BO_ 717 ASCM_2CD: 5 K124_ASCM

BO_ 869 ASCM_365: 4 K124_ASCM

BO_ 1034 ASCM_40A: 7 K124_ASCM

BO_ 1296 ASCM_510: 4 K124_ASCM

BO_ 1930 ASCM_78A: 7 K124_ASCM

BO_ 190 ECMAcceleratorPos: 6 K20_ECM
 SG_ BrakePedalPos : 15|8@0+ (1,0) [0|0] "sticky"  NEO
 SG_ GasPedalAndAcc : 23|8@0+ (1,0) [0|0] ""  NEO

BO_ 201 ECMEngineStatus: 8 K20_ECM
 SG_ EngineTPS : 39|8@0+ (0.392156863,0) [0|100.000000065] "%"  NEO
 SG_ EngineRPM : 15|16@0+ (0.25,0) [0|0] "RPM"  NEO

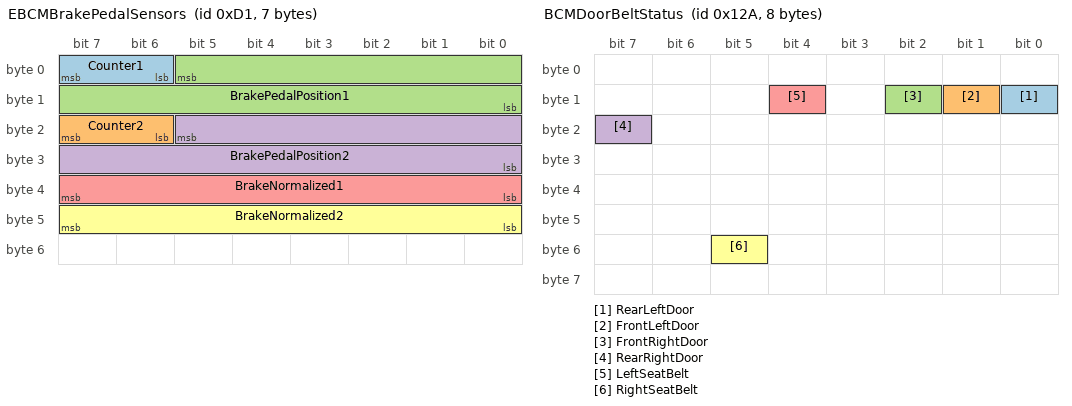
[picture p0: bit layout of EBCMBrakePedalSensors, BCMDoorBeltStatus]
BO_ 209 EBCMBrakePedalSensors: 7 K17_EBCM
 SG_ Counter1 : 7|2@0+ (1,0) [0|3] "" XXX
 SG_ Counter2 : 23|2@0+ (1,0) [0|3] "" XXX
 SG_ BrakePedalPosition1 : 5|14@0+ (1,0) [0|16383] "" XXX
 SG_ BrakePedalPosition2 : 21|14@0- (-1,0) [0|16383] "" XXX
 SG_ BrakeNormalized1 : 39|8@0+ (1,0) [0|255] "" XXX
 SG_ BrakeNormalized2 : 47|8@0- (-1,0) [0|255] "" XXX

BO_ 241 EBCMBrakePedalPosition: 6 K17_EBCM
 SG_ BrakePedalPosition : 15|8@0+ (1,0) [0|255] ""  NEO

BO_ 298 BCMDoorBeltStatus: 8 K9_BCM
 SG_ RearLeftDoor : 8|1@0+ (1,0) [0|0] ""  NEO
 SG_ FrontLeftDoor : 9|1@0+ (1,0) [0|0] ""  NEO
 SG_ FrontRightDoor : 10|1@0+ (1,0) [0|0] ""  NEO
 SG_ RearRightDoor : 23|1@0+ (1,0) [0|0] ""  NEO
 SG_ LeftSeatBelt : 12|1@0+ (1,0) [0|0] ""  NEO
 SG_ RightSeatBelt : 53|1@0+ (1,0) [0|0] ""  NEO

BO_ 309 ECMPRDNL: 8 K20_ECM
 SG_ PRNDL : 2|3@0+ (1,0) [0|0] ""  NEO

BO_ 320 BCMTurnSignals: 3 K9_BCM
 SG_ TurnSignals : 19|2@0+ (1,0) [0|0] ""  NEO

BO_ 336 ASCMLKASStatus: 1 NEO
 SG_ Available : 7|1@0+ (1,0) [0|0] ""  NEO

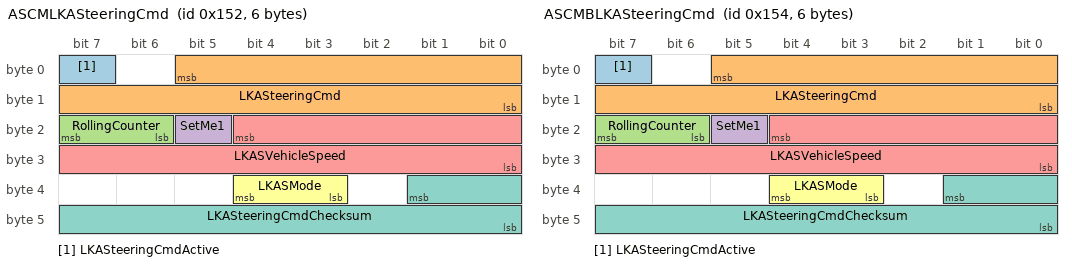
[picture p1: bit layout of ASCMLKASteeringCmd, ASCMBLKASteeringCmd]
BO_ 338 ASCMLKASteeringCmd: 6 NEO
 SG_ LKASteeringCmdActive : 7|1@0+ (1,0) [0|0] ""  NEO
 SG_ LKASteeringCmd : 5|14@0- (1,0) [0|0] ""  NEO
 SG_ RollingCounter : 23|2@0+ (1,0) [0|0] ""  NEO
 SG_ SetMe1 : 21|1@0+ (1,0) [0|0] ""  NEO
 SG_ LKASVehicleSpeed : 20|13@0+ (0.22,0) [0|0] "kph" NEO
 SG_ LKASMode : 36|2@0+ (1,0) [0|0] ""  NEO
 SG_ LKASteeringCmdChecksum : 33|10@0+ (1,0) [0|0] ""  NEO

BO_ 340 ASCMBLKASteeringCmd: 6 NEO
 SG_ LKASteeringCmdActive : 7|1@0+ (1,0) [0|0] ""  NEO
 SG_ LKASteeringCmd : 5|14@0- (1,0) [0|0] ""  NEO
 SG_ RollingCounter : 23|2@0+ (1,0) [0|0] ""  NEO
 SG_ SetMe1 : 21|1@0+ (1,0) [0|0] ""  NEO
 SG_ LKASVehicleSpeed : 20|13@0+ (0.22,0) [0|0] "kph" NEO
 SG_ LKASMode : 36|2@0+ (1,0) [0|0] ""  NEO
 SG_ LKASteeringCmdChecksum : 33|10@0+ (1,0) [0|0] ""  NEO

BO_ 381 MSG_17D: 8 K20_ECM
 SG_ MSG17D_AccPower : 35|12@0- (1,0) [0|0] ""  NEO

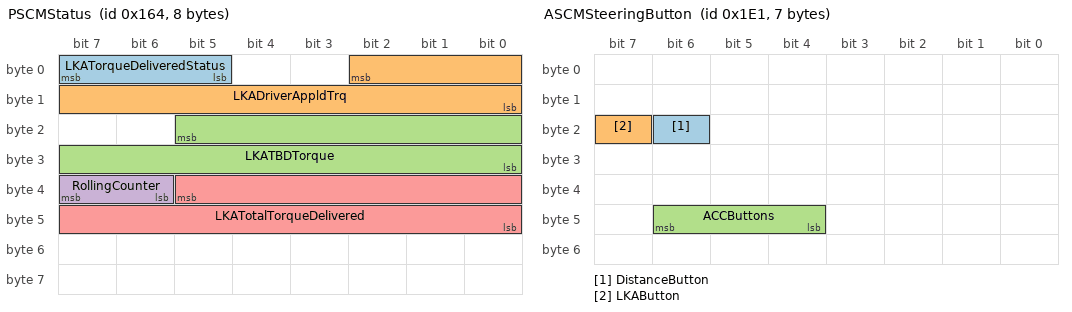
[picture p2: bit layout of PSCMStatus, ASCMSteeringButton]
BO_ 356 PSCMStatus: 8 K43_PSCM
 SG_ LKATorqueDeliveredStatus : 7|3@0+ (1,0) [0|7] ""  NEO
 SG_ LKADriverAppldTrq : 2|11@0- (0.01,0) [-10.24|10.23] "Nm"  NEO
 SG_ LKATBDTorque : 21|14@0- (-0.005,0) [-10.24|10.23] "Nm"  NEO
 SG_ RollingCounter : 39|2@0+ (1,0) [0|0] ""  NEO
 SG_ LKATotalTorqueDelivered : 37|14@0- (0.01,0) [-10.24|10.23] "Nm"  NEO

BO_ 417 AcceleratorPedal: 7 XXX
 SG_ AcceleratorPedal : 55|8@0+ (1,0) [0|0] ""  NEO

BO_ 451 GasAndAcc: 8 XXX
 SG_ GasPedalAndAcc2 : 55|8@0+ (1,0) [0|0] ""  NEO

BO_ 452 AcceleratorPedal2: 8 XXX
 SG_ AcceleratorPedal2 : 47|8@0+ (1,0) [0|0] ""  NEO

BO_ 481 ASCMSteeringButton: 7 K124_ASCM
 SG_ DistanceButton : 22|1@0+ (1,0) [0|0] ""  NEO
 SG_ LKAButton : 23|1@0+ (1,0) [0|0] ""  NEO
 SG_ ACCButtons : 46|3@0+ (1,0) [0|0] ""  NEO

BO_ 485 PSCMSteeringAngle: 8 K43_PSCM
 SG_ SteeringWheelAngle : 15|16@0- (0.0625,0) [-2047|2047] "deg"  NEO
 SG_ SteeringWheelRate : 27|12@0- (1,0) [-2047|2047] "deg/s"  NEO

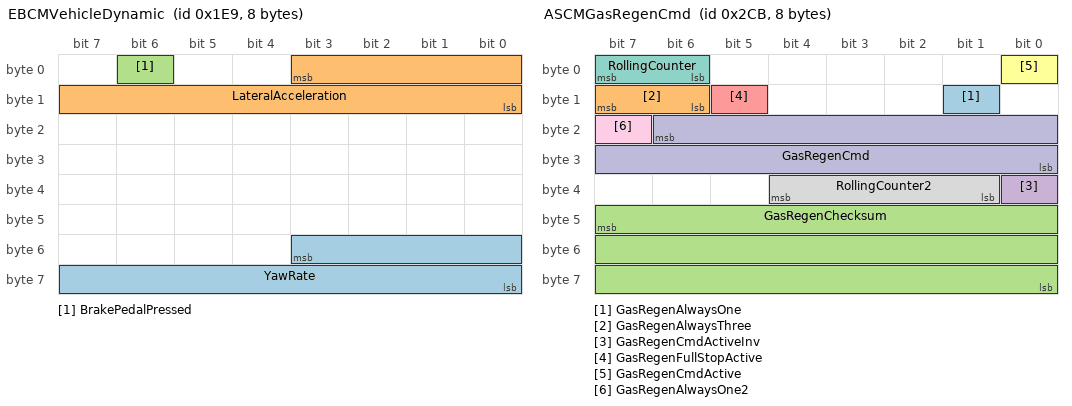
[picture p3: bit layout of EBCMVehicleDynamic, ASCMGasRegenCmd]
BO_ 489 EBCMVehicleDynamic: 8 K17_EBCM
 SG_ YawRate : 51|12@0- (0.0625,0) [-2047|2047] "grad/s"  NEO
 SG_ LateralAcceleration : 3|12@0- (0.0161,0) [-2047|2047] "m/s2"  NEO
 SG_ BrakePedalPressed : 6|1@0+ (1,0) [0|0] ""  NEO

BO_ 711 BECMBatteryVoltageCurrent: 6 K17_EBCM
 SG_ HVBatteryVoltage : 31|12@0+ (0.125,0) [0|511.875] "V"  NEO
 SG_ HVBatteryCurrent : 12|13@0- (0.15,0) [-614.4|614.25] "A"  NEO

BO_ 715 ASCMGasRegenCmd: 8 K124_ASCM
 SG_ GasRegenAlwaysOne : 9|1@0+ (1,1) [1|1] ""  NEO
 SG_ GasRegenAlwaysThree : 15|2@0+ (1,1) [1|1] ""  NEO
 SG_ GasRegenChecksum : 47|24@0+ (1,0) [0|0] ""  NEO
 SG_ GasRegenCmdActiveInv : 32|1@0+ (1,0) [0|0] ""  NEO
 SG_ GasRegenFullStopActive : 13|1@0+ (1,0) [0|0] ""  NEO
 SG_ GasRegenCmdActive : 0|1@0+ (1,0) [0|0] ""  NEO
 SG_ RollingCounter : 7|2@0+ (1,0) [0|0] ""  NEO
 SG_ RollingCounter2 : 36|4@0+ (1,0) [0|0] ""  NEO
 SG_ GasRegenAlwaysOne2 : 23|1@0+ (1,0) [0|1] ""  NEO
 SG_ GasRegenCmd : 22|15@0+ (1,0) [0|0] ""  NEO

BO_ 810 TCICOnStarGPSPosition: 8 K73_TCIC
 SG_ GPSLongitude : 39|32@0+ (1,-2147483648) [0|0] "milliarcsecond"  NEO
 SG_ GPSLatitude : 7|32@0+ (1,0) [0|0] "milliarcsecond"  NEO

BO_ 840 EBCMWheelSpdFront: 4 K17_EBCM
 SG_ FLWheelSpd : 7|16@0+ (0.0311,0) [0|255] "km/h"  NEO
 SG_ FRWheelSpd : 23|16@0+ (0.0311,0) [0|255] "km/h"  NEO

BO_ 842 EBCMWheelSpdRear: 4 K17_EBCM
 SG_ RLWheelSpd : 7|16@0+ (0.0311,0) [0|255] "km/h"  NEO
 SG_ RRWheelSpd : 23|16@0+ (0.0311,0) [0|255] "km/h"  NEO

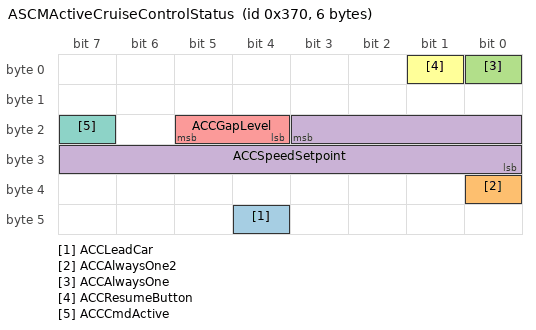
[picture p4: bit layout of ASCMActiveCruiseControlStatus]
BO_ 880 ASCMActiveCruiseControlStatus: 6 K124_ASCM
 SG_ ACCLeadCar : 44|1@0+ (1,0) [0|0] "" Vector__XXX
 SG_ ACCAlwaysOne2 : 32|1@0+ (1,0) [0|0] "" Vector__XXX
 SG_ ACCAlwaysOne : 0|1@0+ (1,0) [0|0] "" Vector__XXX
 SG_ ACCSpeedSetpoint : 19|12@0+ (0.0625,0) [0|255.9375] "km/h"  NEO
 SG_ ACCGapLevel : 21|2@0+ (1,0) [0|0] ""  NEO
 SG_ ACCResumeButton : 1|1@0+ (1,0) [0|0] ""  NEO
 SG_ ACCCmdActive : 23|1@0+ (1,0) [0|0] ""  NEO

BO_ 1001 ECMVehicleSpeed: 8 K20_ECM
 SG_ VehicleSpeed : 7|16@0+ (0.01,0) [0|0] "mph"  NEO

BO_ 1033 ASCMKeepAlive: 7 NEO
 SG_ ASCMKeepAliveAllZero : 7|56@0+ (1,0) [0|0] ""  NEO

BO_ 1217 ECMEngineCoolantTemp: 8 K20_ECM
 SG_ EngineCoolantTemp : 23|8@0+ (1,-40) [0|0] "C"  NEO

BO_ 1249 VIN_Part2: 8 K20_ECM
 SG_ VINPart2 : 7|64@0+ (1,0) [0|0] ""  NEO

BO_ 1300 VIN_Part1: 8 K20_ECM
 SG_ VINPart1 : 7|64@0+ (1,0) [0|0] ""  NEO

BO_ 1912 PSCM_778: 8 K43_PSCM

BO_TX_BU_ 338 : K124_ASCM,NEO;
BO_TX_BU_ 880 : NEO,K124_ASCM;
BO_TX_BU_ 1033 : K124_ASCM,NEO;
BO_TX_BU_ 715 : NEO,K124_ASCM;

CM_ SG_ 85 BrakePedalActive2 "Active during braking";
CM_ SG_ 85 NEW_SIGNAL_1 "Not yet figured out.";
CM_ SG_ 85 BrakePedalActive "Brake pedal pushed";
CM_ SG_ 8 SteeringDirection "1=Right turn, 0=Left turn. Steering wheel pointing left or right from center (0 deg).";
CM_ SG_ 8 RelativeTurnDirection "1=Right turn, 0=Left turn. Steering wheel currently turning the way.";
CM_ SG_ 101 NEW_SIGNAL_1 "Rate of something?";
CM_ SG_ 192 TransmissionGear "0 = 1st gear, 1= 2nd gear...";
CM_ SG_ 681 TurnSignal "0 = Nothing, 1= Left, 3=Right";
CM_ SG_ 681 HighBeamOn "1=HighBeam On, 0=HighBeam Off";
CM_ SG_ 48 ACCStatusTracking "ACC Tracking vehicle, distance control.";
CM_ SG_ 48 ACCStatusOnOff "Turns one after pressing on/off button on steering wheeel";
CM_ SG_ 48 ACCStatusActive "ACC Active";
CM_ SG_ 48 FCWSomething "All bit set during fcw";
CM_ SG_ 48 StatusSomething "Some status changes when zeroing DTCs";
CM_ SG_ 208 TrqLim "Used in checksum calculation, Limit directional torque based on the number.";
CM_ SG_ 208 Checksum "Checksum calculated as a one-complement addition of LKAAngleRequest+LKADirection+Unkown, Zeros used to pad missing bits.";
CM_ SG_ 208 SET_X_02 "Bit 0 = Vibrate steering wheel., Bit 1 = Heartbeat";
CM_ SG_ 352 LkaDimLine "Not true, but follows lka steer direction.";
CM_ SG_ 352 NEW_SIGNAL_1 "Turned one. Got LKA service needed can this be the one?";
CM_ SG_ 640 SpeedTarget "SpeedTarget ACC (noisy bf starting acc Jumps from 0->252->0)";
CM_ SG_ 853 TargetSpeedOdo "Probably target speed odo";
CM_ SG_ 853 LaneMarkingsOdo "Bit 3=Left lane, Bit 2=Right lane, Bit 1=LKA on?, Bit 0=?";
CM_ SG_ 709 SpeedTargetACC "SpeedTargetACC";
CM_ SG_ 224 rate_of_something "Seems to be some kind of torque rather than rate.";
CM_ SG_ 224 OneDuringDriving "Set to 1 when vehicle is rolling.";
CM_ SG_ 293 byte7 "Bit0=0 when gearshift in park, else 1";
CM_ SG_ 293 LKAActive "Bit0=0 when gear in park otherwise =1, Bit1=1 when LKA Active, 0 when not active. Bit2=? Bit3=?";
CM_ SG_ 16 ACCOnOffBtn "Cruise control on/off button pressed";
CM_ SG_ 16 ACCSetBtn "Acc Set button (+) pressed";
CM_ SG_ 16 ACCStopBtn "ACC Stop button pressed";
CM_ SG_ 16 ACCResumeBtn "ACC Resume button pressed";
CM_ SG_ 16 ACCMinusBtn "ACC Minus (-) button pressed";
CM_ SG_ 16 TimeGapIncreaseBtn "Increase the time gap on ACC";
CM_ SG_ 16 TimeGapDecreaseBtn "Decrease the time gap on ACC";
CM_ SG_ 245 counter0 "Speed based counter";
CM_ SG_ 245 WhlSpdLF "Wheel speed left front";
CM_ SG_ 245 WhlSpdRF "Wheel speed right front";
CM_ SG_ 288 WhlSpdLR "Wheel speed left rear";
CM_ SG_ 288 WhlSpdRR "Wheel speed right rear";
CM_ SG_ 64 RPMSomething "TransmissionOutput?";
CM_ SG_ 64 GearShifter "P=0, R=1, N=2, D=3";
CM_ SG_ 272 VehicleSpeedSignal "km/h";
CM_ SG_ 432 BrakePress0 "Brake being pressed";
CM_ SG_ 432 BrakePress1 "Brake being pressed";
CM_ SG_ 432 BrakeStatus "ACC brake?";
CM_ SG_ 437 Counter0 "Related to braking? Maybe one per wheel?";
CM_ SG_ 437 Counter1 "Related to braking? Maybe one per wheel?";
CM_ SG_ 437 Counter2 "Related to braking? Maybe one per wheel?";
CM_ SG_ 437 Counter3 "Related to braking? Maybe one per wheel?";
CM_ SG_ 114 NEW_SIGNAL_1 "Jumped from 0 -> 120 during start. Makes triangle from time to time";
CM_ SG_ 608 NEW_SIGNAL_1 "Status?";
CM_ SG_ 608 NEW_SIGNAL_2 "Classification of object?";
CM_ SG_ 608 Distance "Distance to object in front.";
CM_ SG_ 968 PassengerSeatBelt "1 = Seatbalt latched";
CM_ SG_ 968 DriverSeatBelt "1=Seatbelt latched";
